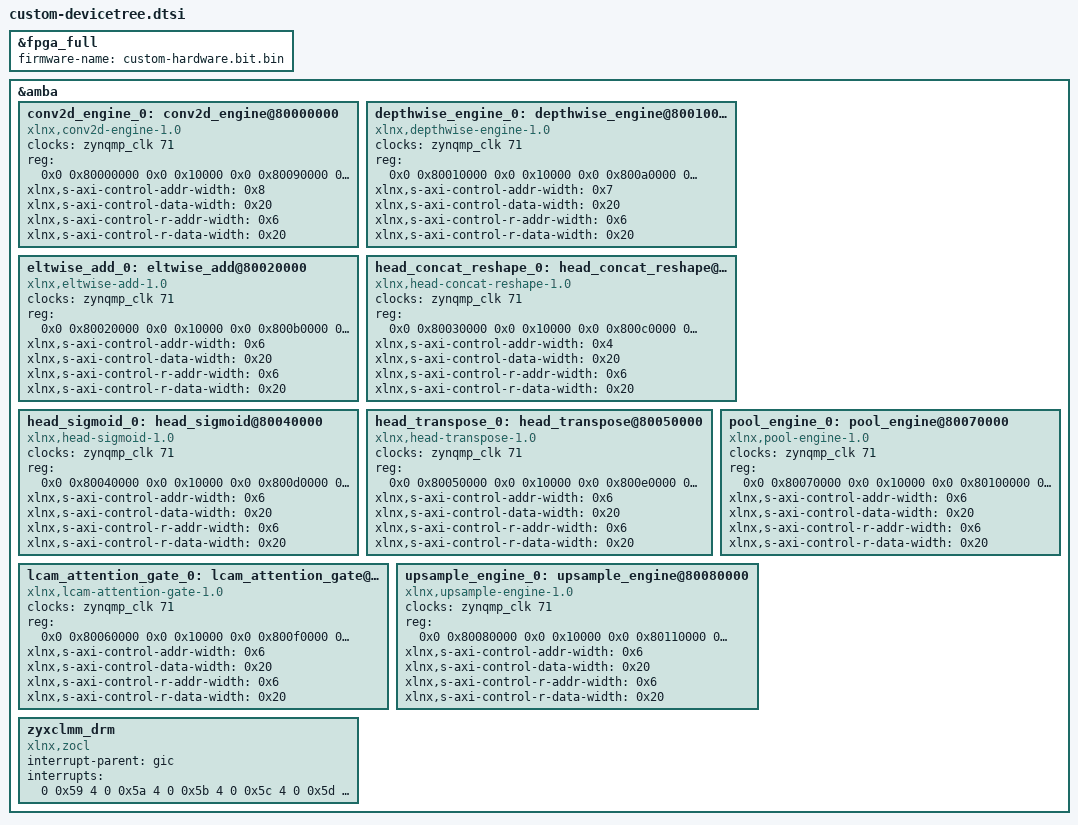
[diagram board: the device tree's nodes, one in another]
// SPDX-License-Identifier: GPL-2.0
/*
 * dts overlay for custom 9-IP no-DPU LCAM-YOLOX accelerator
 */
/dts-v1/;
/plugin/;
&fpga_full {
        #address-cells = <2>;
        #size-cells = <2>;
        firmware-name = "custom-hardware.bit.bin";
};
&amba {
        conv2d_engine_0: conv2d_engine@80000000 {
                clock-names = "ap_clk";
                clocks = <&zynqmp_clk 71>;
                compatible = "xlnx,conv2d-engine-1.0";
                reg = <0x0 0x80000000 0x0 0x10000 0x0 0x80090000 0x0 0x10000>;
                xlnx,s-axi-control-addr-width = <0x8>;
                xlnx,s-axi-control-data-width = <0x20>;
                xlnx,s-axi-control-r-addr-width = <0x6>;
                xlnx,s-axi-control-r-data-width = <0x20>;
        };
        depthwise_engine_0: depthwise_engine@80010000 {
                clock-names = "ap_clk";
                clocks = <&zynqmp_clk 71>;
                compatible = "xlnx,depthwise-engine-1.0";
                reg = <0x0 0x80010000 0x0 0x10000 0x0 0x800a0000 0x0 0x10000>;
                xlnx,s-axi-control-addr-width = <0x7>;
                xlnx,s-axi-control-data-width = <0x20>;
                xlnx,s-axi-control-r-addr-width = <0x6>;
                xlnx,s-axi-control-r-data-width = <0x20>;
        };
        eltwise_add_0: eltwise_add@80020000 {
                clock-names = "ap_clk";
                clocks = <&zynqmp_clk 71>;
                compatible = "xlnx,eltwise-add-1.0";
                reg = <0x0 0x80020000 0x0 0x10000 0x0 0x800b0000 0x0 0x10000>;
                xlnx,s-axi-control-addr-width = <0x6>;
                xlnx,s-axi-control-data-width = <0x20>;
                xlnx,s-axi-control-r-addr-width = <0x6>;
                xlnx,s-axi-control-r-data-width = <0x20>;
        };
        head_concat_reshape_0: head_concat_reshape@80030000 {
                clock-names = "ap_clk";
                clocks = <&zynqmp_clk 71>;
                compatible = "xlnx,head-concat-reshape-1.0";
                reg = <0x0 0x80030000 0x0 0x10000 0x0 0x800c0000 0x0 0x10000>;
                xlnx,s-axi-control-addr-width = <0x4>;
                xlnx,s-axi-control-data-width = <0x20>;
                xlnx,s-axi-control-r-addr-width = <0x6>;
                xlnx,s-axi-control-r-data-width = <0x20>;
        };
        head_sigmoid_0: head_sigmoid@80040000 {
                clock-names = "ap_clk";
                clocks = <&zynqmp_clk 71>;
                compatible = "xlnx,head-sigmoid-1.0";
                reg = <0x0 0x80040000 0x0 0x10000 0x0 0x800d0000 0x0 0x10000>;
                xlnx,s-axi-control-addr-width = <0x6>;
                xlnx,s-axi-control-data-width = <0x20>;
                xlnx,s-axi-control-r-addr-width = <0x6>;
                xlnx,s-axi-control-r-data-width = <0x20>;
        };
        /*
         * NOTE: This reflects the ORIGINAL two-interface (control/control_r)
         * register layout. head_transpose.cpp in hls_ip_sources/ was later
         * modified to a single-interface layout as a debugging experiment
         * (see PROJECT_HISTORY.md §23) -- that fix was tested and RULED OUT
         * as the root cause, so it does not need to be propagated here
         * unless you're specifically re-testing that exact experiment, in
         * which case use debug_scripts/test_head_transpose_v2.py's register
         * scheme instead (single CTRL_BASE, no control_r).
         */
        head_transpose_0: head_transpose@80050000 {
                clock-names = "ap_clk";
                clocks = <&zynqmp_clk 71>;
                compatible = "xlnx,head-transpose-1.0";
                reg = <0x0 0x80050000 0x0 0x10000 0x0 0x800e0000 0x0 0x10000>;
                xlnx,s-axi-control-addr-width = <0x6>;
                xlnx,s-axi-control-data-width = <0x20>;
                xlnx,s-axi-control-r-addr-width = <0x6>;
                xlnx,s-axi-control-r-data-width = <0x20>;
        };
        lcam_attention_gate_0: lcam_attention_gate@80060000 {
                clock-names = "ap_clk";
                clocks = <&zynqmp_clk 71>;
                compatible = "xlnx,lcam-attention-gate-1.0";
                reg = <0x0 0x80060000 0x0 0x10000 0x0 0x800f0000 0x0 0x10000>;
                xlnx,s-axi-control-addr-width = <0x6>;
                xlnx,s-axi-control-data-width = <0x20>;
                xlnx,s-axi-control-r-addr-width = <0x6>;
                xlnx,s-axi-control-r-data-width = <0x20>;
        };
        pool_engine_0: pool_engine@80070000 {
                clock-names = "ap_clk";
                clocks = <&zynqmp_clk 71>;
                compatible = "xlnx,pool-engine-1.0";
                reg = <0x0 0x80070000 0x0 0x10000 0x0 0x80100000 0x0 0x10000>;
                xlnx,s-axi-control-addr-width = <0x6>;
                xlnx,s-axi-control-data-width = <0x20>;
                xlnx,s-axi-control-r-addr-width = <0x6>;
                xlnx,s-axi-control-r-data-width = <0x20>;
        };
        upsample_engine_0: upsample_engine@80080000 {
                clock-names = "ap_clk";
                clocks = <&zynqmp_clk 71>;
                compatible = "xlnx,upsample-engine-1.0";
                reg = <0x0 0x80080000 0x0 0x10000 0x0 0x80110000 0x0 0x10000>;
                xlnx,s-axi-control-addr-width = <0x6>;
                xlnx,s-axi-control-data-width = <0x20>;
                xlnx,s-axi-control-r-addr-width = <0x6>;
                xlnx,s-axi-control-r-data-width = <0x20>;
        };
        zyxclmm_drm {
                compatible = "xlnx,zocl";
                status = "okay";
                interrupt-parent = <&gic>;
                interrupts = <0 0x59 4 0 0x5a 4 0 0x5b 4 0 0x5c 4 0 0x5d 4 0 0x5e 4 0 0x5f 4 0 0x60 4>;
        };
};
